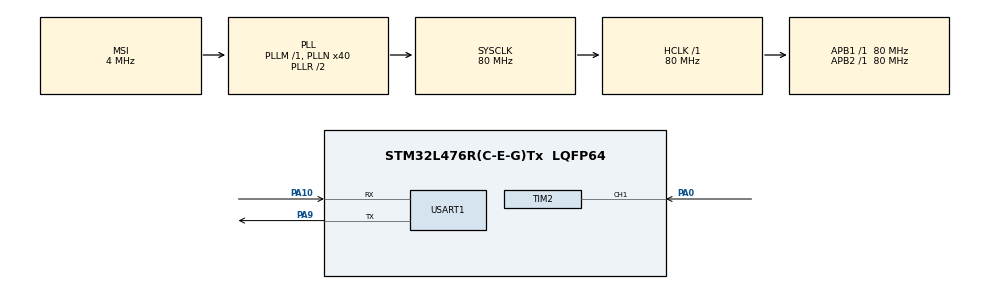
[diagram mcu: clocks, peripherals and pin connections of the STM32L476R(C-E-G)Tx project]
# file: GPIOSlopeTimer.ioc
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Mcu.Family=STM32L4
Mcu.Name=STM32L476R(C-E-G)Tx
Mcu.Package=LQFP64
NVIC.PriorityGroup=NVIC_PRIORITYGROUP_4
NVIC.TIM2_IRQn=true\:0\:0\:false\:false\:true\:true\:true\:true
NVIC.USART1_IRQn=true\:0\:0\:false\:false\:true\:true\:true\:true
PA0.GPIO_PuPd=GPIO_NOPULL
PA0.GPIO_Speed=GPIO_SPEED_FREQ_VERY_HIGH
PA0.Signal=S_TIM2_CH1
PA10.Mode=Asynchronous
PA10.Signal=USART1_RX
PA9.Mode=Asynchronous
PA9.Signal=USART1_TX
ProjectManager.HeapSize=0x200
ProjectManager.StackSize=0x400
ProjectManager.TargetToolchain=STM32CubeIDE
RCC.AHBFreq_Value=80000000
RCC.APB1Freq_Value=80000000
RCC.APB1TimFreq_Value=80000000
RCC.APB2Freq_Value=80000000
RCC.APB2TimFreq_Value=80000000
RCC.CortexFreq_Value=80000000
RCC.HCLKFreq_Value=80000000
RCC.HSE_VALUE=8000000
RCC.HSI_VALUE=16000000
RCC.LSE_VALUE=32768
RCC.MSI_VALUE=4000000
RCC.PLLN=40
RCC.SYSCLKFreq_VALUE=80000000
RCC.SYSCLKSource=RCC_SYSCLKSOURCE_PLLCLK
RCC.VCOOutputFreq_Value=160000000
SH.S_TIM2_CH1.0=TIM2_CH1,Input_Capture1_from_TI1
TIM2.Channel-Input_Capture1_from_TI1=TIM_CHANNEL_1
TIM2.ICPolarity_CH1=TIM_INPUTCHANNELPOLARITY_BOTHEDGE
USART1.VirtualMode-Asynchronous=VM_ASYNC
VP_TIM2_VS_ClockSourceINT.Mode=Internal
board=custom

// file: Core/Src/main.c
/* USER CODE BEGIN Header */
/**
  ******************************************************************************
  * @file           : main.c
  * @brief          : Main program body
  ******************************************************************************
  * @attention
  *
  * Copyright (c) 2025 STMicroelectronics.
  * All rights reserved.
  *
  * This software is licensed under terms that can be found in the LICENSE file
  * in the root directory of this software component.
  * If no LICENSE file comes with this software, it is provided AS-IS.
  *
  ******************************************************************************
  */
/* USER CODE END Header */
#include "main.h"

/* USER CODE BEGIN Includes */
#include <stdio.h>
#include <string.h>
/* USER CODE END Includes */

TIM_HandleTypeDef htim2;

UART_HandleTypeDef huart1;

/* USER CODE BEGIN PV */
void SystemClock_Config(void);
static void MX_GPIO_Init(void);
static void MX_TIM2_Init(void);
/* USER CODE END PV */

void SystemClock_Config(void);
static void MX_GPIO_Init(void);
static void MX_TIM2_Init(void);
static void MX_USART1_UART_Init(void);

/* USER CODE BEGIN 0 */
// Override _write to redirect printf to UART
int _write(int file, char *data, int len)
{
    HAL_UART_Transmit(&huart1, (uint8_t *)data, len, HAL_MAX_DELAY);
    return len;
}
/* USER CODE END 0 */

int main(void)
{

  /* MCU Configuration--------------------------------------------------------*/

  /* Reset of all peripherals, Initializes the Flash interface and the Systick. */
  HAL_Init();

  /* Configure the system clock */
  SystemClock_Config();

  /* Initialize all configured peripherals */
  MX_GPIO_Init();
  MX_TIM2_Init();
  MX_USART1_UART_Init();
  /* USER CODE BEGIN 2 */
  // Start TIM2 Input Capture Interrupt on Channel 1
  if (HAL_TIM_IC_Start_IT(&htim2, TIM_CHANNEL_1) != HAL_OK) {
	  Error_Handler(); // Handle error if Input Capture start fails
  }
  /* USER CODE END 2 */

  /* Infinite loop */
  while (1)
  {

  }
}

void SystemClock_Config(void)
{
  RCC_OscInitTypeDef RCC_OscInitStruct = {0};
  RCC_ClkInitTypeDef RCC_ClkInitStruct = {0};

  /** Configure the main internal regulator output voltage
  */
  if (HAL_PWREx_ControlVoltageScaling(PWR_REGULATOR_VOLTAGE_SCALE1) != HAL_OK)
  {
    Error_Handler();
  }

  /** Initializes the RCC Oscillators according to the specified parameters
  * in the RCC_OscInitTypeDef structure.
  */
  RCC_OscInitStruct.OscillatorType = RCC_OSCILLATORTYPE_MSI;
  RCC_OscInitStruct.MSIState = RCC_MSI_ON;
  RCC_OscInitStruct.MSICalibrationValue = 0;
  RCC_OscInitStruct.MSIClockRange = RCC_MSIRANGE_6;
  RCC_OscInitStruct.PLL.PLLState = RCC_PLL_ON;
  RCC_OscInitStruct.PLL.PLLSource = RCC_PLLSOURCE_MSI;
  RCC_OscInitStruct.PLL.PLLM = 1;
  RCC_OscInitStruct.PLL.PLLN = 40;
  RCC_OscInitStruct.PLL.PLLP = RCC_PLLP_DIV7;
  RCC_OscInitStruct.PLL.PLLQ = RCC_PLLQ_DIV2;
  RCC_OscInitStruct.PLL.PLLR = RCC_PLLR_DIV2;
  if (HAL_RCC_OscConfig(&RCC_OscInitStruct) != HAL_OK)
  {
    Error_Handler();
  }

  /** Initializes the CPU, AHB and APB buses clocks
  */
  RCC_ClkInitStruct.ClockType = RCC_CLOCKTYPE_HCLK|RCC_CLOCKTYPE_SYSCLK
                              |RCC_CLOCKTYPE_PCLK1|RCC_CLOCKTYPE_PCLK2;
  RCC_ClkInitStruct.SYSCLKSource = RCC_SYSCLKSOURCE_PLLCLK;
  RCC_ClkInitStruct.AHBCLKDivider = RCC_SYSCLK_DIV1;
  RCC_ClkInitStruct.APB1CLKDivider = RCC_HCLK_DIV1;
  RCC_ClkInitStruct.APB2CLKDivider = RCC_HCLK_DIV1;

  if (HAL_RCC_ClockConfig(&RCC_ClkInitStruct, FLASH_LATENCY_4) != HAL_OK)
  {
    Error_Handler();
  }
}

static void MX_TIM2_Init(void)
{

  TIM_ClockConfigTypeDef sClockSourceConfig = {0};
  TIM_MasterConfigTypeDef sMasterConfig = {0};
  TIM_IC_InitTypeDef sConfigIC = {0};

  htim2.Instance = TIM2;
  htim2.Init.Prescaler = 0;
  htim2.Init.CounterMode = TIM_COUNTERMODE_UP;
  htim2.Init.Period = 4294967295;
  htim2.Init.ClockDivision = TIM_CLOCKDIVISION_DIV1;
  htim2.Init.AutoReloadPreload = TIM_AUTORELOAD_PRELOAD_DISABLE;
  if (HAL_TIM_Base_Init(&htim2) != HAL_OK)
  {
    Error_Handler();
  }
  sClockSourceConfig.ClockSource = TIM_CLOCKSOURCE_INTERNAL;
  if (HAL_TIM_ConfigClockSource(&htim2, &sClockSourceConfig) != HAL_OK)
  {
    Error_Handler();
  }
  if (HAL_TIM_IC_Init(&htim2) != HAL_OK)
  {
    Error_Handler();
  }
  sMasterConfig.MasterOutputTrigger = TIM_TRGO_RESET;
  sMasterConfig.MasterSlaveMode = TIM_MASTERSLAVEMODE_DISABLE;
  if (HAL_TIMEx_MasterConfigSynchronization(&htim2, &sMasterConfig) != HAL_OK)
  {
    Error_Handler();
  }
  sConfigIC.ICPolarity = TIM_INPUTCHANNELPOLARITY_BOTHEDGE;
  sConfigIC.ICSelection = TIM_ICSELECTION_DIRECTTI;
  sConfigIC.ICPrescaler = TIM_ICPSC_DIV1;
  sConfigIC.ICFilter = 0;
  if (HAL_TIM_IC_ConfigChannel(&htim2, &sConfigIC, TIM_CHANNEL_1) != HAL_OK)
  {
    Error_Handler();
  }

}

static void MX_USART1_UART_Init(void)
{

  huart1.Instance = USART1;
  huart1.Init.BaudRate = 115200;
  huart1.Init.WordLength = UART_WORDLENGTH_8B;
  huart1.Init.StopBits = UART_STOPBITS_1;
  huart1.Init.Parity = UART_PARITY_NONE;
  huart1.Init.Mode = UART_MODE_TX_RX;
  huart1.Init.HwFlowCtl = UART_HWCONTROL_NONE;
  huart1.Init.OverSampling = UART_OVERSAMPLING_16;
  huart1.Init.OneBitSampling = UART_ONE_BIT_SAMPLE_DISABLE;
  huart1.AdvancedInit.AdvFeatureInit = UART_ADVFEATURE_NO_INIT;
  if (HAL_UART_Init(&huart1) != HAL_OK)
  {
    Error_Handler();
  }

}

static void MX_GPIO_Init(void)
{

  /* GPIO Ports Clock Enable */
  __HAL_RCC_GPIOA_CLK_ENABLE();

}

void Error_Handler(void)
{
  __disable_irq();
  while (1)
  {
  }
}
